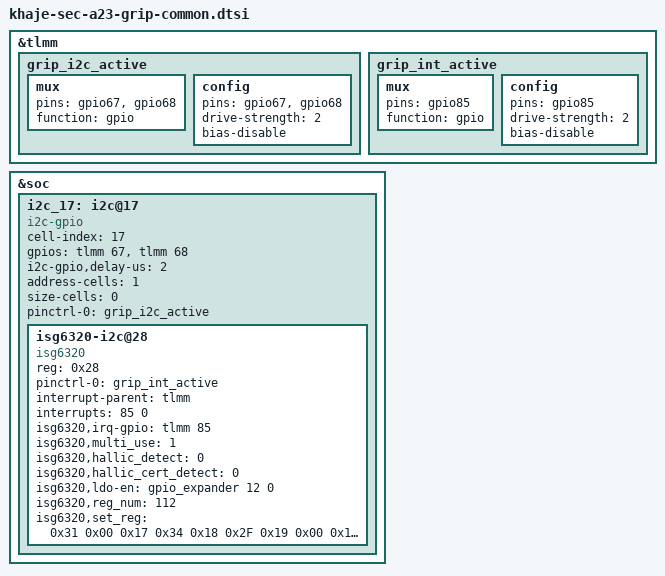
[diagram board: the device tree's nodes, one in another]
/* Copyright (c) 2019, The Linux Foundation. All rights reserved.
 *
 * This program is free software; you can redistribute it and/or modify
 * it under the terms of the GNU General Public License version 2 and
 * only version 2 as published by the Free Software Foundation.
 *
 * This program is distributed in the hope that it will be useful,
 * but WITHOUT ANY WARRANTY; without even the implied warranty of
 * MERCHANTABILITY or FITNESS FOR A PARTICULAR PURPOSE.  See the
 * GNU General Public License for more details.
 */

&tlmm {
	grip_i2c_active: grip_i2c_active {
		mux {
			pins = "gpio67", "gpio68";
			function = "gpio";
		};
		config {
			pins = "gpio67", "gpio68";
			drive-strength = <2>;
			bias-disable;
		};
	};

	grip_int_active: grip_int_active {
		mux {
			pins = "gpio85";
			function = "gpio";
		};
		config {
			pins = "gpio85";
			drive-strength = <2>;
			bias-disable;
		};
	};
};

&soc {
	i2c_17: i2c@17 { /* SW I2C */
		status = "ok";

		cell-index = <17>;
		compatible = "i2c-gpio";
		gpios = <&tlmm 67 0 /* sda */
			 &tlmm 68 0 /* scl */
		>;
		i2c-gpio,delay-us = <2>;
		address-cells = <1>;
		size-cells = <0>;
		pinctrl-names = "default";
		pinctrl-0 = <&grip_i2c_active>;
		isg6320-i2c@28 {
			compatible = "isg6320";
			reg = <0x28>;
			status = "okay";
			pinctrl-names = "default";
			pinctrl-0 = <&grip_int_active>;
			interrupt-parent = <&tlmm>;
			interrupts = <85 0>;

			isg6320,irq-gpio = <&tlmm 85 0>;

			isg6320,multi_use = <1>;
			isg6320,hallic_detect = <0>;
			isg6320,hallic_cert_detect = <0>;
			isg6320,ldo-en = <&gpio_expander 12 0>;
			isg6320,reg_num = <112>;
			isg6320,set_reg = /bits/ 8 <
				0x31 0x00
				0x17 0x34
				0x18 0x2F
				0x19 0x00
				0x1A 0x1A
				0x1B 0x12
				0x1C 0x1A
				0x1D 0x2D
				0x1E 0x00
				0x1F 0x05
				0x20 0x12
				0x21 0x12
				0x22 0x20
				0x23 0x2D
				0x24 0x05
				0x25 0x20
				0x26 0x2D
				0x27 0x05
				0x28 0x12
				0x2B 0x27
				0x38 0x54
				0x60 0x05
				0x61 0x5F
				0x62 0x7F
				0x91 0x7F
				0x65 0x12
				0x67 0x4B
				0x68 0x96
				0x69 0x40
				0x6A 0x00
				0x6C 0x80
				0x6D 0x82
				0x6E 0x44
				0x6F 0x08
				0x70 0x60
				0x71 0x80
				0x72 0x40
				0x73 0x00
				0x74 0xED
				0x75 0x40
				0x76 0xFD
				0x77 0x80
				0x78 0xFD
				0x79 0xA0
				0x7C 0x15
				0x7D 0x1A
				0x7E 0x6D
				0x80 0x03
				0x81 0x4E
				0x89 0x01
				0x8A 0x69
				0x8B 0x7D
				0x8C 0x7D
				0x94 0x05
				0x95 0x50
				0x96 0x52
				0xC5 0x51
				0x99 0x12
				0x9B 0x4B
				0x9C 0x96
				0x9D 0x40
				0x9E 0x00
				0xA0 0x80
				0xA1 0xB3
				0xA2 0x44
				0xA3 0x08
				0xA4 0x60
				0xA5 0x80
				0xA6 0x40
				0xA7 0x00
				0xA8 0xED
				0xA9 0x40
				0xAA 0xFD
				0xAB 0x80
				0xAC 0xFD
				0xAD 0xA0
				0xB0 0x15
				0xB1 0x1A
				0xB2 0x6D
				0xB4 0x03
				0xB5 0x4E
				0xBD 0x01
				0xBE 0x69
				0xBF 0x7D
				0xC0 0x7D
				0x51 0x08
				0x52 0x13
				0x55 0x10
				0x56 0x30
				0x59 0x20
				0x5A 0x20
				0xD1 0x04
				0xD2 0x10
				0xD5 0x10
				0xD6 0x30
				0xD9 0x20
				0xDA 0x14
				0x37 0x33
				0x90 0x13
				0xC4 0x13
				0x05 0xB8
				0x06 0x80
				0x07 0x0D
				0x08 0x01
				0x09 0x80
				0x0F 0xAB
				0x11 0x09
				0x12 0x08
				0x14 0x33
				0x15 0x13
				0x16 0x13
				0x2C 0x03
				>;
		};
	};
};
